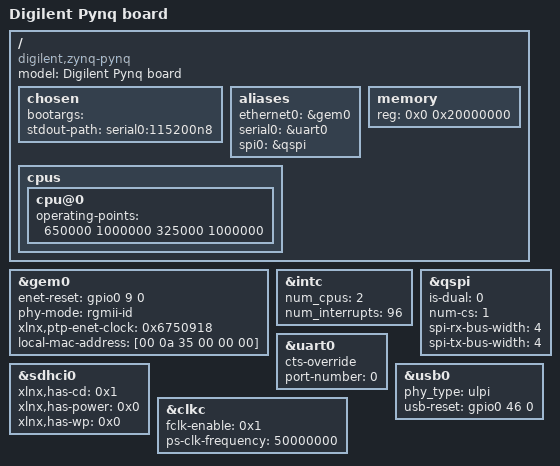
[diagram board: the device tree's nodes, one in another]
 /dts-v1/;
/include/ "zynq-7000.dtsi"

/ {
	model = "Digilent Pynq board";
	compatible = "digilent,zynq-pynq", "xlnx,zynq-7000";
	
	chosen {
		bootargs = "";
		stdout-path = "serial0:115200n8";
	};
	aliases {
		ethernet0 = &gem0;
		serial0 = &uart0;
		spi0 = &qspi;
	};
	memory {
		device_type = "memory";
		reg = <0x0 0x20000000>;
	};
};

/ {
	cpus {
		cpu@0 {
			operating-points = <650000 1000000 325000 1000000>;
		};
	};
};

&gem0 {
	enet-reset = <&gpio0 9 0>;
	phy-mode = "rgmii-id";
	status = "okay";
	xlnx,ptp-enet-clock = <0x6750918>;
	local-mac-address = [00 0a 35 00 00 00];
};

&intc {
	num_cpus = <2>;
	num_interrupts = <96>;
};

&qspi {
	is-dual = <0>;
	num-cs = <1>;
	spi-rx-bus-width = <4>;
	spi-tx-bus-width = <4>;
	status = "okay";
};

&sdhci0 {
	status = "okay";
	xlnx,has-cd = <0x1>;
	xlnx,has-power = <0x0>;
	xlnx,has-wp = <0x0>;
};

&uart0 {
	cts-override ;
	device_type = "serial";
	port-number = <0>;
	status = "okay";
};

&usb0 {
	phy_type = "ulpi";
	status = "okay";
	usb-reset = <&gpio0 46 0>;
};

&clkc {
	fclk-enable = <0x1>;
	ps-clk-frequency = <50000000>;
};
